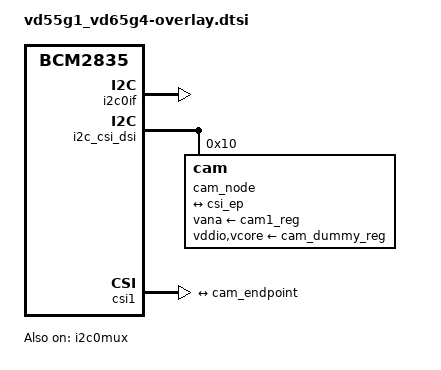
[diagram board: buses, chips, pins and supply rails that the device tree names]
// SPDX-License-Identifier: GPL-2.0-only
/dts-v1/;
/plugin/;

/{
	compatible = "brcm,bcm2835";

	fragment@0 {
		target = <&i2c0if>;
		__overlay__ {
			status = "okay";
		};
	};

	clk_frag: fragment@1 {
		target = <&cam1_clk>;
		__overlay__ {
			status = "okay";
			clock-frequency = <12000000>;
		};
	};

	fragment@2 {
		target = <&i2c0mux>;
		__overlay__ {
			status = "okay";
		};
	};

	i2c_frag: fragment@3 {
		target = <&i2c_csi_dsi>;
		__overlay__ {
			#address-cells = <1>;
			#size-cells = <0>;
			status = "okay";

			cam_node: cam@10 {
				reg = <0x10>;
				status = "disabled";

				clocks = <&cam1_clk>;
				clock-names = "xclk";

				vana-supply = <&cam1_reg>;	/* 2.8v */
				vddio-supply = <&cam_dummy_reg>;	/* 1.8v */
				vcore-supply = <&cam_dummy_reg>;	/* 1.2v */

				rotation = <0>;
				orientation = <2>;

				st,leds = <2>;

				port {
					cam_endpoint: endpoint {
						clock-lanes = <0>;
						data-lanes = <1>;
						clock-noncontinuous;
						link-frequencies =
							/bits/ 64 <600000000>;
						lane-polarities = <1 1>;
					};
				};
			};
		};
	};

	csi_frag: fragment@4 {
		target = <&csi1>;
		csi: __overlay__ {
			status = "okay";

			port {
				csi_ep: endpoint {
					remote-endpoint = <&cam_endpoint>;
					clock-lanes = <0>;
					data-lanes = <1>;
					clock-noncontinuous;
				};
			};
		};
	};

	fragment@5 {
		target = <&csi1>;
		__dormant__ {
			compatible = "brcm,bcm2835-unicam-legacy";
		};
	};

	__overrides__ {
		rotation = <&cam_node>,"rotation:0";
		orientation = <&cam_node>,"orientation:0";
		media-controller = <0>,"!5";
		cam0 = <&i2c_frag>, "target:0=",<&i2c_csi_dsi0>,
		       <&csi_frag>, "target:0=",<&csi0>,
		       <&clk_frag>, "target:0=",<&cam0_clk>,
		       <&cam_node>, "clocks:0=",<&cam0_clk>,
		       <&cam_node>, "vana-supply:0=",<&cam0_reg>;
	};
};

&cam_node {
	status = "okay";
};

&cam_endpoint {
	remote-endpoint = <&csi_ep>;
};
